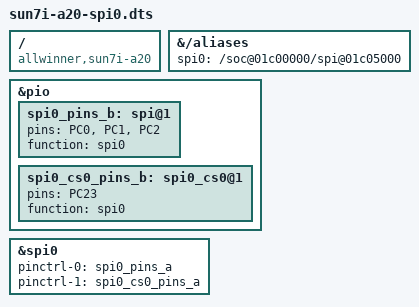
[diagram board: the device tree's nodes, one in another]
/dts-v1/;
/plugin/;

/ {
	compatible = "allwinner,sun7i-a20";

	fragment@0 {
		target-path = "/aliases";
		__overlay__ {
			spi0 = "/soc@01c00000/spi@01c05000";
		};
	};

	fragment@1 {
		target = <&pio>;
		__overlay__ {
			spi0_pins_b: spi@1 {
				pins = "PC0", "PC1", "PC2";
				function = "spi0";
			};

			spi0_cs0_pins_b: spi0_cs0@1 {
				pins = "PC23";
				function = "spi0";
			};
		};
	};

	fragment@2 {
		target = <&spi0>;
		__overlay__ {
			status = "okay";
			pinctrl-names = "default", "default";
			pinctrl-0 = <&spi0_pins_a>;
			pinctrl-1 = <&spi0_cs0_pins_a>;
		};
	};
};
